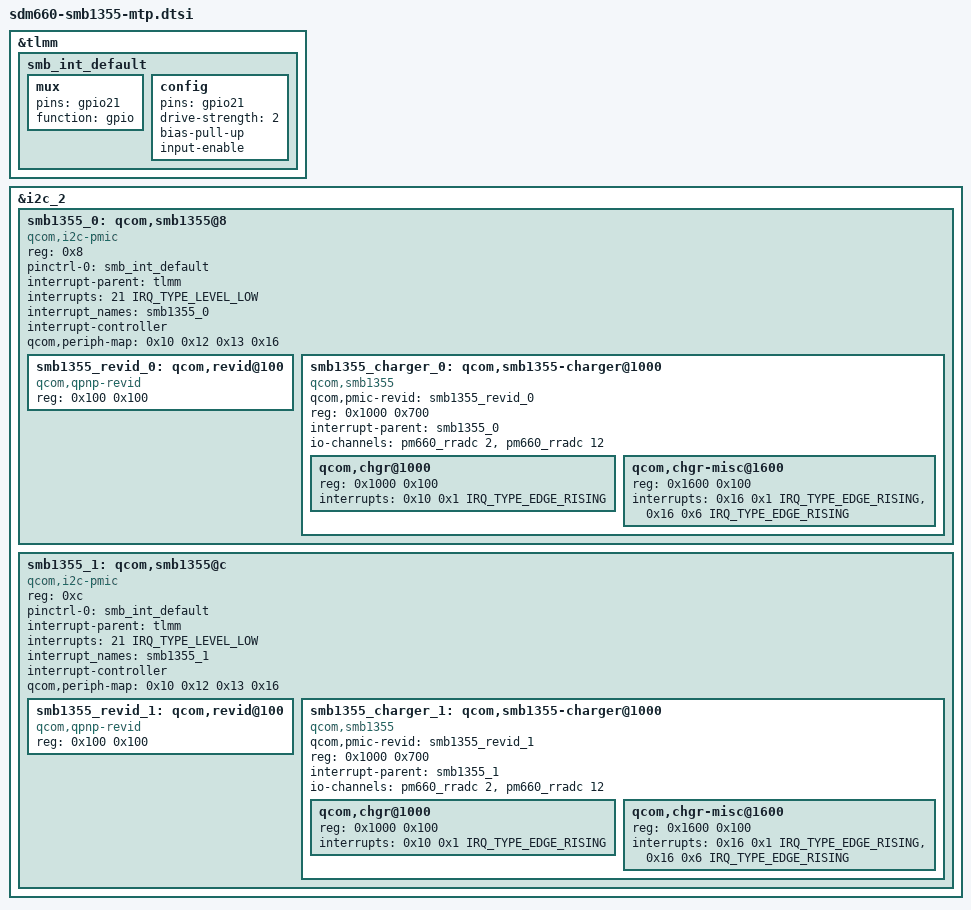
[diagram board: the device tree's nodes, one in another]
/* Copyright (c) 2018, The Linux Foundation. All rights reserved.
 * Copyright (C) 2019 XiaoMi, Inc.
 *
 * This program is free software; you can redistribute it and/or modify
 * it under the terms of the GNU General Public License version 2 and
 * only version 2 as published by the Free Software Foundation.
 *
 * This program is distributed in the hope that it will be useful,
 * but WITHOUT ANY WARRANTY; without even the implied warranty of
 * MERCHANTABILITY or FITNESS FOR A PARTICULAR PURPOSE.  See the
 * GNU General Public License for more details.
 */

&tlmm {
	smb_int_default: smb_int_default {
		mux {
			pins = "gpio21";
			function = "gpio";
		};
		config {
			pins = "gpio21";
			drive-strength = <2>;
			bias-pull-up;
			input-enable;
		};
	};
};

&i2c_2 {
	status = "ok";
	smb1355_0: qcom,smb1355@8 {
		compatible = "qcom,i2c-pmic";
		reg = <0x8>;
		#address-cells = <1>;
		#size-cells = <0>;
		pinctrl-names = "default";
		pinctrl-0 = <&smb_int_default>;
		interrupt-parent = <&tlmm>;
		interrupts = <21 IRQ_TYPE_LEVEL_LOW>;
		interrupt_names = "smb1355_0";
		interrupt-controller;
		#interrupt-cells = <3>;
		qcom,periph-map = <0x10 0x12 0x13 0x16>;

		smb1355_revid_0: qcom,revid@100 {
			compatible = "qcom,qpnp-revid";
			reg = <0x100 0x100>;
		};

		smb1355_charger_0: qcom,smb1355-charger@1000 {
			compatible = "qcom,smb1355";
			qcom,pmic-revid = <&smb1355_revid_0>;
			reg = <0x1000 0x700>;
			#address-cells = <1>;
			#size-cells = <1>;
			interrupt-parent = <&smb1355_0>;
			/* qcom,parallel-mode = <1>; */
			/* qcom,stacked-batfet; */
			status = "ok";

			io-channels = <&pm660_rradc 2>,
				      <&pm660_rradc 12>;
			io-channel-names = "charger_temp",
					   "charger_temp_max";

			qcom,chgr@1000 {
				reg = <0x1000 0x100>;
				interrupts = <0x10 0x1 IRQ_TYPE_EDGE_RISING>;
				interrupt-names = "chg-state-change";
			};

			qcom,chgr-misc@1600 {
				reg = <0x1600 0x100>;
				interrupts = <0x16 0x1 IRQ_TYPE_EDGE_RISING>,
					     <0x16 0x6 IRQ_TYPE_EDGE_RISING>;
				interrupt-names = "wdog-bark",
						  "temperature-change";
			};
		};
	};

	smb1355_1: qcom,smb1355@c {
		compatible = "qcom,i2c-pmic";
		reg = <0xc>;
		#address-cells = <1>;
		#size-cells = <0>;
		pinctrl-names = "default";
		pinctrl-0 = <&smb_int_default>;
		interrupt-parent = <&tlmm>;
		interrupts = <21 IRQ_TYPE_LEVEL_LOW>;
		interrupt_names = "smb1355_1";
		interrupt-controller;
		#interrupt-cells = <3>;
		qcom,periph-map = <0x10 0x12 0x13 0x16>;

		smb1355_revid_1: qcom,revid@100 {
			compatible = "qcom,qpnp-revid";
			reg = <0x100 0x100>;
		};

		smb1355_charger_1: qcom,smb1355-charger@1000 {
			compatible = "qcom,smb1355";
			qcom,pmic-revid = <&smb1355_revid_1>;
			reg = <0x1000 0x700>;
			#address-cells = <1>;
			#size-cells = <1>;
			interrupt-parent = <&smb1355_1>;
			/* qcom,parallel-mode = <1>; */
			/* qcom,stacked-batfet; */
			status = "ok";

			io-channels = <&pm660_rradc 2>,
				      <&pm660_rradc 12>;
			io-channel-names = "charger_temp",
					   "charger_temp_max";

			qcom,chgr@1000 {
				reg = <0x1000 0x100>;
				interrupts = <0x10 0x1 IRQ_TYPE_EDGE_RISING>;
				interrupt-names = "chg-state-change";
			};

			qcom,chgr-misc@1600 {
				reg = <0x1600 0x100>;
				interrupts = <0x16 0x1 IRQ_TYPE_EDGE_RISING>,
					     <0x16 0x6 IRQ_TYPE_EDGE_RISING>;
				interrupt-names = "wdog-bark",
						  "temperature-change";
			};
		};
	};
};
